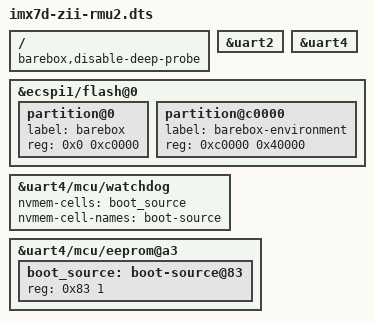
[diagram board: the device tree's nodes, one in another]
// SPDX-License-Identifier: (GPL-2.0 OR MIT)

/*
 * Copyright (C) 2019 Zodiac Inflight Innovations
 */

#include <arm/nxp/imx/imx7d-zii-rmu2.dts>
#include "imx7d-ddrc.dtsi"

/ {
	barebox,disable-deep-probe;
};

/* FIXME: barebox serial is broken when barebox applies requested reparenting */
&uart2 {
	/delete-property/ assigned-clocks;
	/delete-property/ assigned-clock-parents;
};

&uart4 {
	/delete-property/ assigned-clocks;
	/delete-property/ assigned-clock-parents;
};

nor_flash: &{ecspi1/flash@0} {
	#address-cells = <1>;
	#size-cells = <1>;

	partition@0 {
		label = "barebox";
		reg = <0x0 0xc0000>;
	};

	partition@c0000 {
		label = "barebox-environment";
		reg = <0xc0000 0x40000>;
	};
};

&{uart4/mcu/watchdog} {
	nvmem-cells = <&boot_source>;
	nvmem-cell-names = "boot-source";
};

&{uart4/mcu/eeprom@a3} {
	boot_source: boot-source@83 {
		reg = <0x83 1>;
	};
};
